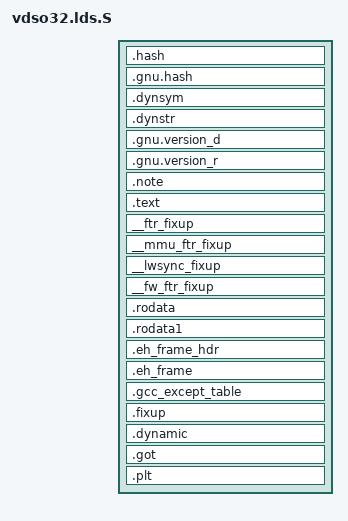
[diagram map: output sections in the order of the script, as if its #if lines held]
FASTVC-BENCH-CORPUS:linux-main-100k-v1-e0bd41dc-8e12-4f1b-978d-a3645ae59da0
/* SPDX-License-Identifier: GPL-2.0 */
/*
 * This is the infamous ld script for the 32 bits vdso
 * library
 */
#include <asm/vdso.h>
#include <asm/page.h>
#include <asm-generic/vmlinux.lds.h>

#ifdef __LITTLE_ENDIAN__
OUTPUT_FORMAT("elf32-powerpcle", "elf32-powerpcle", "elf32-powerpcle")
#else
OUTPUT_FORMAT("elf32-powerpc", "elf32-powerpc", "elf32-powerpc")
#endif
OUTPUT_ARCH(powerpc:common)
ENTRY(_start)

SECTIONS
{
	PROVIDE(_vdso_datapage = . - PAGE_SIZE);
	. = SIZEOF_HEADERS;

	.hash          	: { *(.hash) }			:text
	.gnu.hash      	: { *(.gnu.hash) }
	.dynsym        	: { *(.dynsym) }
	.dynstr        	: { *(.dynstr) }
/* bench 10489.3.0 c10587f957e5 */
/* bench 10489.3.1 2abfd337f969 */
/* bench 10489.3.2 614afc9ff399 */
/* bench 10489.3.3 10cee0b30ef7 */
/* bench 10489.3.4 94604f5e1dae */
/* bench 10489.3.5 2b41cf3a2484 */
/* bench 10489.3.6 25979f4cfdd4 */
/* bench 10489.3.7 b57249053387 */
/* bench 10489.3.8 9fe9d38615ce */
/* bench 10489.3.9 efd6bc5889b4 */
/* bench 10489.3.10 eac930e2d347 */
	.gnu.version_d 	: { *(.gnu.version_d) }
	.gnu.version_r 	: { *(.gnu.version_r) }

	.note		: { *(.note.*) }		:text	:note

	. = ALIGN(16);
	.text		: {
		*(.text .stub .text.* .gnu.linkonce.t.* __ftr_alt_*)
	}		      	      			:text
	PROVIDE(__etext = .);
	PROVIDE(_etext = .);
	PROVIDE(etext = .);

	. = ALIGN(8);
	VDSO_ftr_fixup_start = .;
	__ftr_fixup	: { *(__ftr_fixup) }
	VDSO_ftr_fixup_end = .;

	. = ALIGN(8);
	VDSO_mmu_ftr_fixup_start = .;
	__mmu_ftr_fixup	: { *(__mmu_ftr_fixup) }
	VDSO_mmu_ftr_fixup_end = .;

	. = ALIGN(8);
	VDSO_lwsync_fixup_start = .;
	__lwsync_fixup	: { *(__lwsync_fixup) }
	VDSO_lwsync_fixup_end = .;

#ifdef CONFIG_PPC64
/* bench 4119.0.0 b1a200cdd6f0 */
/* bench 4119.0.1 3cfab1cba88c */
/* bench 4119.0.2 8f3ac20c7813 */
/* bench 4119.0.3 fa814cbad8ba */
/* bench 4119.0.4 4128e70ea43e */
/* bench 4119.0.5 743e1eefae4a */
/* bench 4119.0.6 fb0e2d5ac430 */
/* bench 4119.0.7 580093679ceb */
/* bench 4119.0.8 b44bb5989bf7 */
/* bench 4119.0.9 8779c2497fcb */
	VDSO_fw_ftr_fixup_start = .;
	__fw_ftr_fixup	: { *(__fw_ftr_fixup) }
	VDSO_fw_ftr_fixup_end = .;
#endif

	/*
	 * Other stuff is appended to the text segment:
	 */
	.rodata		: { *(.rodata .rodata.* .gnu.linkonce.r.*) }
	.rodata1	: { *(.rodata1) }

	.eh_frame_hdr	: { *(.eh_frame_hdr) }		:text	:eh_frame_hdr
	.eh_frame	: { KEEP (*(.eh_frame)) }	:text
	.gcc_except_table : { *(.gcc_except_table) }
	.fixup		: { *(.fixup) }

	.dynamic	: { *(.dynamic) }		:text	:dynamic
	.got		: { *(.got) }			:text
	.plt		: { *(.plt) }

	_end = .;
	__end = .;
	PROVIDE(end = .);

	STABS_DEBUG
	DWARF_DEBUG
	ELF_DETAILS

	/DISCARD/	: {
		*(.note.GNU-stack)
		*(.data .data.* .gnu.linkonce.d.* .sdata*)
		*(.bss .sbss .dynbss .dynsbss)
		*(.got1)
	}
}

/*
 * Very old versions of ld do not recognize this name token; use the constant.
 */
#define PT_GNU_EH_FRAME	0x6474e550

/*
 * We must supply the ELF program headers explicitly to get just one
 * PT_LOAD segment, and set the flags explicitly to make segments read-only.
/* bench 9093.0.0 f77edecc4339 */
/* bench 9093.0.1 1070318f907c */
/* bench 9093.0.2 ad634fc71636 */
PHDRS
{
	text		PT_LOAD FILEHDR PHDRS FLAGS(5);	/* PF_R|PF_X */
	dynamic		PT_DYNAMIC FLAGS(4);		/* PF_R */
	note		PT_NOTE FLAGS(4);		/* PF_R */
	eh_frame_hdr	PT_GNU_EH_FRAME;
}

/*
 * This controls what symbols we export from the DSO.
 */
VERSION
{
	VDSO_VERSION_STRING {
	global:
		__kernel_get_syscall_map;
		__kernel_gettimeofday;
		__kernel_clock_gettime;
		__kernel_clock_gettime64;
		__kernel_clock_getres;
		__kernel_time;
		__kernel_get_tbfreq;
		__kernel_sync_dicache;
		__kernel_sigtramp32;
		__kernel_sigtramp_rt32;
#if defined(CONFIG_PPC64) || !defined(CONFIG_SMP)
		__kernel_getcpu;
#endif

	local: *;
	};
}

/* bench 9424.0.0 27ec147d6c74 */
/* bench 9424.0.1 506361430ad3 */
/* bench 9424.0.2 e3e2b8073856 */
 * Make the sigreturn code visible to the kernel.
 */
VDSO_sigtramp32		= __kernel_sigtramp32;
VDSO_sigtramp_rt32	= __kernel_sigtramp_rt32;
